# vpac_targetdb register map
Vendor: Texas Instruments
Registers are 32-bit, read-write, no defined reset value unless marked. A register's access mark holds for its fields unless they carry their own. Offsets are as the file gives them; [hi:lo] are bit positions; {n}, {i} and the like mark numbered series; 'fields as' and 'values as' point back to an identical list.

## VPAC (part 8 of 8) — Vision Pre-Processing Accelerator (VPAC)
{0xC1C+0x20*i} msram3_fw_region_{i}_end_address_h (i=0..7) — The FW Region {i} End Address High Register defines the end address bits 47 to 32 to include for the slave ksbus_msram3.slv region {i} firewall.
  [15:0] end_address_h — End address bits 47 to 32 to include in the match.
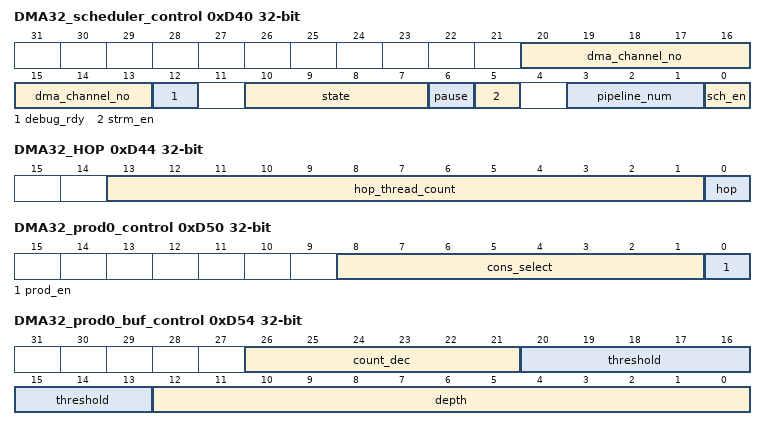
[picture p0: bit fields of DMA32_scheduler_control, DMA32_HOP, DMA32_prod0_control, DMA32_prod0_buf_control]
0xD40 DMA32_scheduler_control access per field — Scheduler Control Register
  [20:13] dma_channel_no rw — DMA channel number for thread scheduler for DMA32
  [12] debug_rdy rw — '0' -> DMA32 Scheduler resources must not be read during halted state. '1'-> DMA32 Scheduler resources are readable during halted state
  [10:7] state ro — Current state of DMA32 Scheduler
  [6] pause rw — '1' -> pause/suspend scheduler , '0' -> resume scheduler
  [5] strm_en rw — '1' -> Streaming input enable, '0' No streaming input
  [3:1] pipeline_num rw — Pipeline Number of DMA32 Scheduler
  [0] sch_en rw — scheduler enable; write '1' to enable scheduler
0xD44 DMA32_HOP — Scheduler HOP Control Register. Help in detecting eop within scheduler. Once configured, it counts task/channel starts and stops issuing further starts. Specifically useful for Head of pipe dma scheduler .
  [13:1] hop_thread_count — Number of Task count for Head of pipe
  [0] hop — '1' -> Head of Pipe producer Sch , '0' -> No hop
0xD50 DMA32_prod0_control — Controlling producer socket0 for DMA32
  [8:1] cons_select — consumer select for DMA32 prod socket 0. Used in decrementing count of producer buffer
  [0] prod_en — '1' -> Producer socket 0 enable , '0' Disable
0xD54 DMA32_prod0_buf_control — Controlling producer socket0 buffer for DMA32
  [26:21] count_dec — Count decrement value for prod count
  [20:13] threshold — Count threshold to generate pend for consumer
  [12:0] depth — Maximum number of producer buffer count
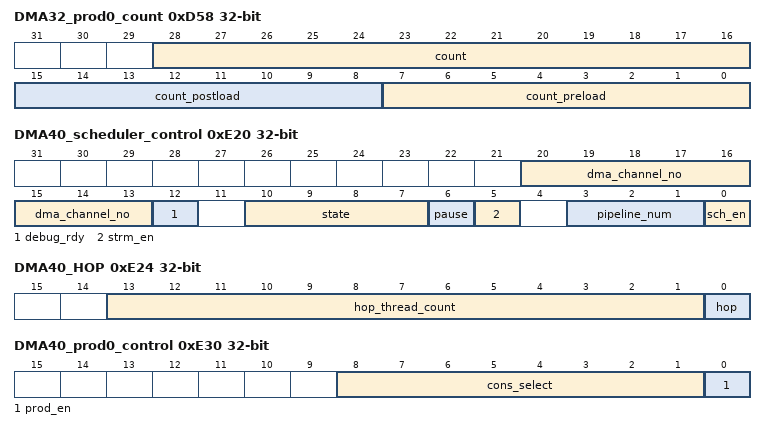
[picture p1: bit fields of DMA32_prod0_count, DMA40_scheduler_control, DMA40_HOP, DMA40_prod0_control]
0xD58 DMA32_prod0_count access per field — Defining count values for pre/post load for generating pend by DMA32 prod0
  [28:16] count ro — current count value
  [15:8] count_postload rw — count postload after producer max thread count reached
  [7:0] count_preload rw — count preload after scheduler start/init
0xE20 DMA40_scheduler_control access per field — Scheduler Control Register
  [20:13] dma_channel_no rw — DMA channel number for thread scheduler for DMA40
  [12] debug_rdy rw — '0' -> DMA40 Scheduler resources must not be read during halted state. '1'-> DMA40 Scheduler resources are readable during halted state
  [10:7] state ro — Current state of DMA40 Scheduler
  [6] pause rw — '1' -> pause/suspend scheduler , '0' -> resume scheduler
  [5] strm_en rw — '1' -> Streaming input enable, '0' No streaming input
  [3:1] pipeline_num rw — Pipeline Number of DMA40 Scheduler
  [0] sch_en rw — scheduler enable; write '1' to enable scheduler
0xE24 DMA40_HOP — Scheduler HOP Control Register. Help in detecting eop within scheduler. Once configured, it counts task/channel starts and stops issuing further starts. Specifically useful for Head of pipe dma scheduler .
  fields as DMA32_HOP
0xE30 DMA40_prod0_control — Controlling producer socket0 for DMA40
  [8:1] cons_select — consumer select for DMA40 prod socket 0. Used in decrementing count of producer buffer
  [0] prod_en — '1' -> Producer socket 0 enable , '0' Disable
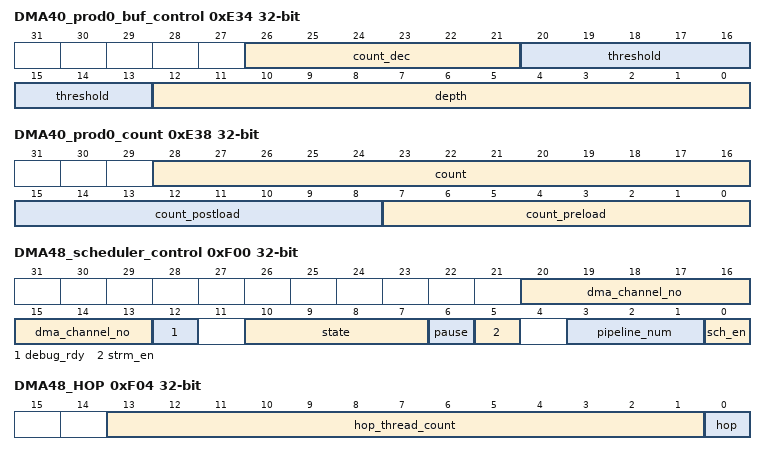
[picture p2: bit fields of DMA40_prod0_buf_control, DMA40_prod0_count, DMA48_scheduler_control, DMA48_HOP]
0xE34 DMA40_prod0_buf_control — Controlling producer socket0 buffer for DMA40
  fields as DMA32_prod0_buf_control
0xE38 DMA40_prod0_count access per field — Defining count values for pre/post load for generating pend by DMA40 prod0
  fields as DMA32_prod0_count
0xF00 DMA48_scheduler_control access per field — Scheduler Control Register
  [20:13] dma_channel_no rw — DMA channel number for thread scheduler for DMA48
  [12] debug_rdy rw — '0' -> DMA48 Scheduler resources must not be read during halted state. '1'-> DMA48 Scheduler resources are readable during halted state
  [10:7] state ro — Current state of DMA48 Scheduler
  [6] pause rw — '1' -> pause/suspend scheduler , '0' -> resume scheduler
  [5] strm_en rw — '1' -> Streaming input enable, '0' No streaming input
  [3:1] pipeline_num rw — Pipeline Number of DMA48 Scheduler
  [0] sch_en rw — scheduler enable; write '1' to enable scheduler
0xF04 DMA48_HOP — Scheduler HOP Control Register. Help in detecting eop within scheduler. Once configured, it counts task/channel starts and stops issuing further starts. Specifically useful for Head of pipe dma scheduler .
  fields as DMA32_HOP
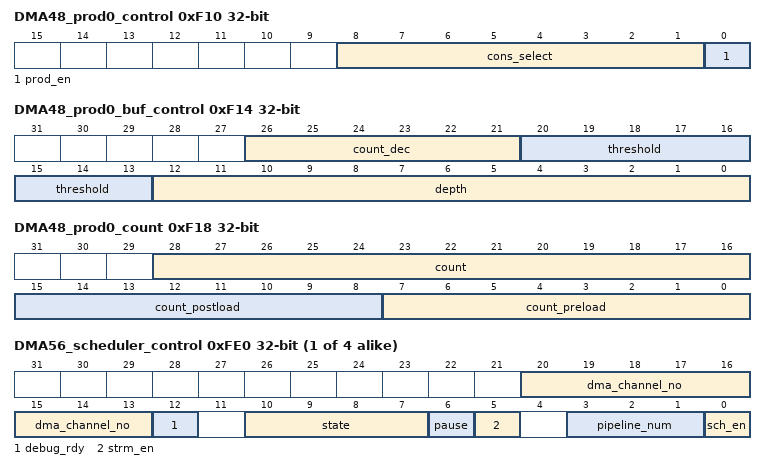
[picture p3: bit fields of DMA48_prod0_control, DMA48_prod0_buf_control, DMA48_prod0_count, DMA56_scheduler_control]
0xF10 DMA48_prod0_control — Controlling producer socket0 for DMA48
  [8:1] cons_select — consumer select for DMA48 prod socket 0. Used in decrementing count of producer buffer
  [0] prod_en — '1' -> Producer socket 0 enable , '0' Disable
0xF14 DMA48_prod0_buf_control — Controlling producer socket0 buffer for DMA48
  fields as DMA32_prod0_buf_control
0xF18 DMA48_prod0_count access per field — Defining count values for pre/post load for generating pend by DMA48 prod0
  fields as DMA32_prod0_count
{0x9C0+0x1C*i} DMA{i}_scheduler_control access per field (i=56..59) — Scheduler Control Register
  [20:13] dma_channel_no rw — DMA channel number for thread scheduler for DMA{i}
  [12] debug_rdy rw — '0' -> DMA{i} Scheduler resources must not be read during halted state. '1'-> DMA{i} Scheduler resources are readable during halted state
  [10:7] state ro — Current state of DMA{i} Scheduler
  [6] pause rw — '1' -> pause/suspend scheduler , '0' -> resume scheduler
  [5] strm_en rw — '1' -> Streaming input enable, '0' No streaming input
  [3:1] pipeline_num rw — Pipeline Number of DMA{i} Scheduler
  [0] sch_en rw — scheduler enable; write '1' to enable scheduler
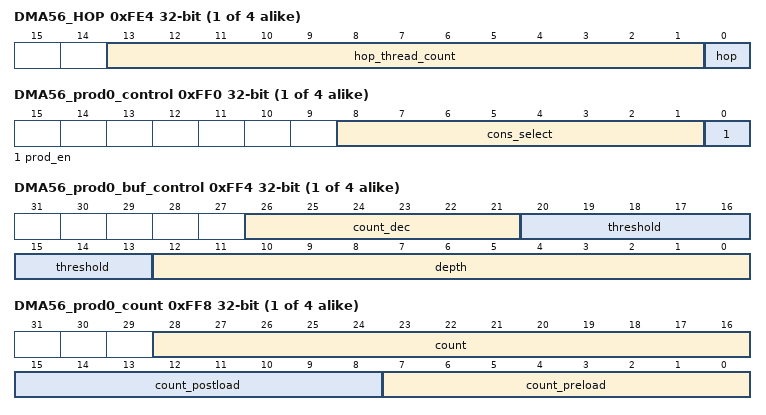
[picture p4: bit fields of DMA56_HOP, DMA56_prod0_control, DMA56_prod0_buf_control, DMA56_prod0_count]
{0x9C4+0x1C*i} DMA{i}_HOP (i=56..59) — Scheduler HOP Control Register. Help in detecting eop within scheduler. Once configured, it counts task/channel starts and stops issuing further starts. Specifically useful for Head of pipe dma scheduler .
  fields as DMA32_HOP
{0x9D0+0x1C*i} DMA{i}_prod0_control (i=56..59) — Controlling producer socket0 for DMA{i}
  [8:1] cons_select — consumer select for DMA{i} prod socket 0. Used in decrementing count of producer buffer
  [0] prod_en — '1' -> Producer socket 0 enable , '0' Disable
{0x9D4+0x1C*i} DMA{i}_prod0_buf_control (i=56..59) — Controlling producer socket0 buffer for DMA{i}
  fields as DMA32_prod0_buf_control
{0x9D8+0x1C*i} DMA{i}_prod0_count access per field (i=56..59) — Defining count values for pre/post load for generating pend by DMA{i} prod0
  fields as DMA32_prod0_count
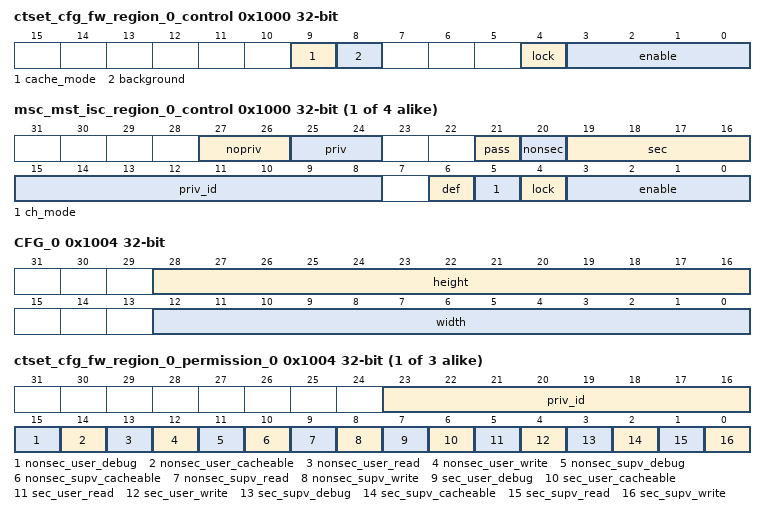
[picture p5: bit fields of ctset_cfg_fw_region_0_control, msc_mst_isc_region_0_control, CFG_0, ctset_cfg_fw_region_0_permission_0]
0x1000 ctset_cfg_fw_region_0_control — The FW Region 0 Control Register defines the control fields for the slave ctset2_wrap.cfg region 0 firewall.
  [9] cache_mode — Cache mode for region. Set to 1 to check cache permissions. Set to 0 to ignore cache permissions.
  [8] background — Background enable for region. There can be 1 backgroun region per FW and foreground regions can have overlapping addresses only with the background region.
  [4] lock — Lock region. Once set region values cannot be modified.
  [3:0] enable — Enable region. A value of 0xA enables, others disable.
{0x1000+0x20*i} msc_mst_isc_region_{i}_control access per field (i=0..3) — The ISC Region {i} Control Register defines the control fields for the master .msc_mst region {i} ISC.
  [27:26] nopriv rw — Clear output priv attribute. If each bit is set then the outgoing priv bit is cleared.
  [25:24] priv rw — Set outgoing priv attribute. If each bit is set then the outgoing priv bit is set.
  [21] pass rw — No privID replacement, pass through value.
  [20] nonsec rw — Make outgoing non-secure.
  [19:16] sec rw — Make outgoing secure. A value of 0xA enables, others disable.
  [15:8] priv_id rw
  [6] def ro — Default region indication. The default region is used when all other regions do not match.
  [5] ch_mode rw — Enable channel mode to match region to a chanid value. Otherwise use address mode to match region to an address range.
  [4] lock rw — Lock region. Once set the region values cannot be modified.
  [3:0] enable rw — Enable region. A value of 0xA enables, others disable.
0x1004 CFG_0 — The Control Register controls the input width and height of the module.
  [28:16] height — Height of the input image
  [12:0] width — Width of the input image
{0x1004+4i} ctset_cfg_fw_region_0_permission_{i} (i=0..2) — The FW Region 0 Permission {i} Register defines the permissions for the slave ctset2_wrap.cfg region 0 firewall.
  [23:16] priv_id — Allowed privid.
  [15] nonsec_user_debug — Non-secure user debug allowed.
  [14] nonsec_user_cacheable — Non-secure user cacheable allowed.
  [13] nonsec_user_read — Non-secure user read allowed.
  [12] nonsec_user_write — Non-secure user write allowed.
  [11] nonsec_supv_debug — Non-secure supervisor debug allowed.
  [10] nonsec_supv_cacheable — Non-secure supervisor cacheable allowed.
  [9] nonsec_supv_read — Non-secure supervisor read allowed.
  [8] nonsec_supv_write — Non-secure supervisor write allowed.
  [7] sec_user_debug — Secure user debug allowed.
  [6] sec_user_cacheable — Secure user cacheable allowed.
  [5] sec_user_read — Secure user read allowed.
  [4] sec_user_write — Secure user write allowed.
  [3] sec_supv_debug — Secure supervisor debug allowed.
  [2] sec_supv_cacheable — Secure supervisor cacheable allowed.
  [1] sec_supv_read — Secure supervisor read allowed.
  [0] sec_supv_write — Secure supervisor write allowed.
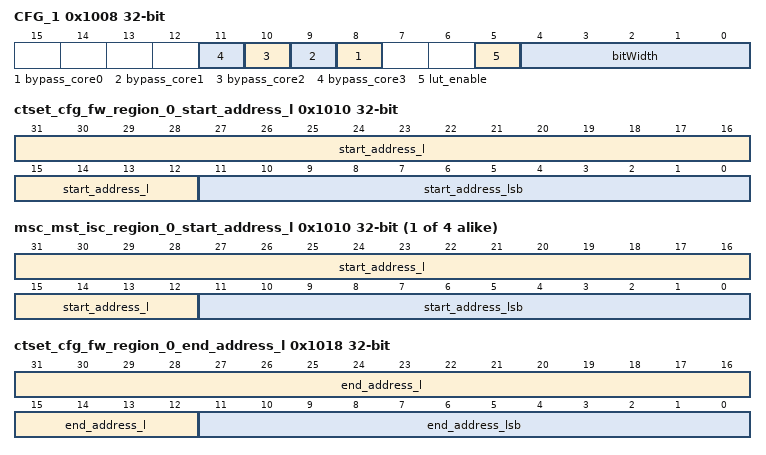
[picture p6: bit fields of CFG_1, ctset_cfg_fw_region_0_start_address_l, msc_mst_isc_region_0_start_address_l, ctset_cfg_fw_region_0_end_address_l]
0x1008 CFG_1 — The Control Register identifies the bit width of the input image
  [n+8] bypass_core{n} (n=0..3) — Setting the ~ibypass_core{n} bit will bypass filtering operation, output = input
  [5] lut_enable — 0->Use shift(bitwidth-12) ,1->Use LUT
  [4:0] bitWidth — BitWidth of the input image, values greater than 16 will be treated as 16 and values less than 12 will be treated as 12.
0x1008 LINE_SEL — Selector for which line memory is read or written
  [2:0] line_selector — Selects which line is read or written from the line memory array. The current line is updated at Start-Of-Line, so if the memory is read during a line that is being written, the data for the current_line will contain the new data for this current_line as well as old data from current_line - 5 that has not been overridden yet. If the current_line is the first few lines of a frame, the other lines will be from the end of the previous frame. '0' = current line written, '1' = current line - 1, 2 = current line - 2, 3 = current line - 3, 4 = current side band line. 5 = current side band line - 1.
0x1010 ctset_cfg_fw_region_0_start_address_l access per field — The FW Region 0 Start Address Low Register defines the start address bits 31 to 0 for the slave ctset2_wrap.cfg region 0 firewall.
  [31:12] start_address_l rw — Start address bits 31 to 12. Lowest 12 bits are forced to 0 as address must be 4KB aligned.
  [11:0] start_address_lsb ro — Start address bits 11 to 0 are forced to 0 as address must be 4KB aligned.
{0x1010+0x20*i} msc_mst_isc_region_{i}_start_address_l (i=0..3) — The ISC Region {i} Start Address Low Register defines the start address bits 31 to 0 for the master .msc_mst region {i} ISC.
  [31:12] start_address_l — Start address bits 31 to 12.
  [11:0] start_address_lsb — Start address bits 11 to 0 must be 0 as address must be 4KB aligned in address mode. Can also be channel number in channel mode.
0x1014 ctset_cfg_fw_region_0_start_address_h — The FW Region 0 Start Address High Register defines the start address bits 47 to 32 for the slave ctset2_wrap.cfg region 0 firewall.
  [15:0] start_address_h — Start address bits 47 to 32.
{0x1014+0x20*i} msc_mst_isc_region_{i}_start_address_h (i=0..3) — The ISC Region {i} Start Address High Register defines the start address bits 47 to 32 for the master .msc_mst region {i} ISC.
  [15:0] start_address_h — Start address bits 47 to 32.
0x1018 ctset_cfg_fw_region_0_end_address_l access per field — The FW Region 0 End Address Low Register defines the end address bits 31 to 0 to include for the slave ctset2_wrap.cfg region 0 firewall.
  [31:12] end_address_l rw — End address bits 31 to 12 to include in the match. Lowest 12 bits are forced to 1s as address must be 4KB aligned.
  [11:0] end_address_lsb ro — End address bits 11 to 0 are forced to 1s as address must be 4KB aligned minus 1.
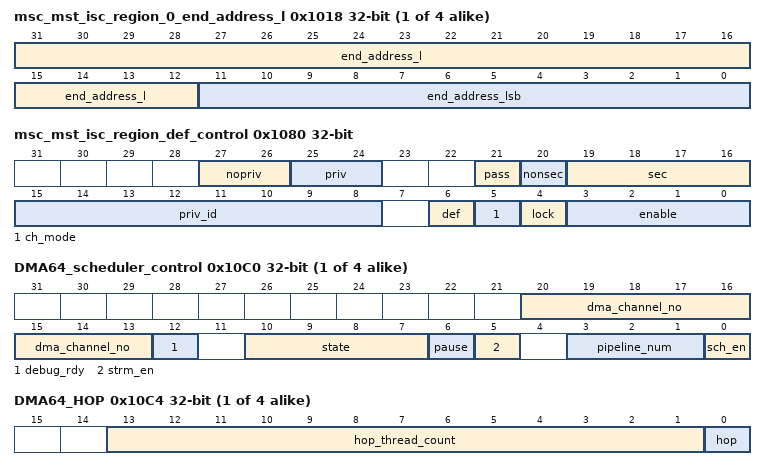
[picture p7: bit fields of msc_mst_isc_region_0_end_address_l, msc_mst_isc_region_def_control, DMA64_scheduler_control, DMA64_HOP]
{0x1018+0x20*i} msc_mst_isc_region_{i}_end_address_l access per field (i=0..3) — The ISC Region {i} End Address Low Register defines the end included address bits 31 to 0 for the master .msc_mst region {i} ISC.
  [31:12] end_address_l rw — End address bits 31 to 12 to include in the match.
  [11:0] end_address_lsb ro — End address bits 11 to 0 are forced to Fs as address must be 4KB aligned.
0x101C ctset_cfg_fw_region_0_end_address_h — The FW Region 0 End Address High Register defines the end address bits 47 to 32 to include for the slave ctset2_wrap.cfg region 0 firewall.
  fields as msram3_fw_region_0_end_address_h
{0x101C+0x20*i} msc_mst_isc_region_{i}_end_address_h (i=0..3) — The ISC Region {i} End Address High Register defines the end address bits 47 to 32 for the master .msc_mst region {i} ISC.
  [15:0] end_address_h — End address bits 47 to 32.
0x1080 msc_mst_isc_region_def_control access per field — The ISC Default Region Control Register defines the control fields for the master .msc_mst region 4 ISC.
  [27:26] nopriv rw — Clear output priv attribute. If each bit is set then the outgoing priv bit is cleared.
  [25:24] priv rw — Set outgoing priv attribute. If each bit is set then the outgoing priv bit is set.
  [21] pass rw — No privID replacement, pass through value.
  [20] nonsec rw — Make outgoing non-secure.
  [19:16] sec rw — Make outgoing secure. A value of 0xA enables, others disable.
  [15:8] priv_id rw
  [6] def ro — Default region indication. The default region is used when all other regions do not match.
  [5] ch_mode ro — Enable channel mode to match region to a chanid value. Otherwise use address mode to match region to an address range.
  [4] lock rw — Lock region. Once set, the region values cannot be modified.
  [3:0] enable ro — Enable region. A value of 0xA enables, others disable.
{0x9C0+0x1C*i} DMA{i}_scheduler_control access per field (i=64..67) — Scheduler Control Register
  fields as DMA56_scheduler_control
{0x9C4+0x1C*i} DMA{i}_HOP (i=64..67) — Scheduler HOP Control Register. Help in detecting eop within scheduler. Once configured, it counts task/channel starts and stops issuing further starts. Specifically useful for Head of pipe dma scheduler .
  fields as DMA32_HOP
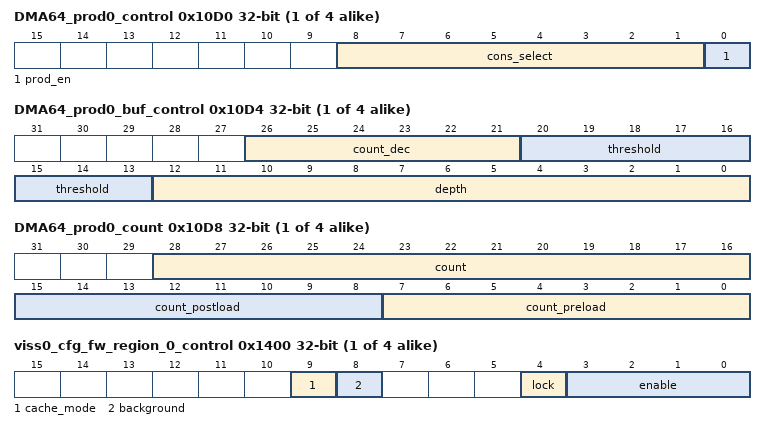
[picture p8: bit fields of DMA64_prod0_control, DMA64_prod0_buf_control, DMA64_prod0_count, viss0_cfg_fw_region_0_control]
{0x9D0+0x1C*i} DMA{i}_prod0_control (i=64..67) — Controlling producer socket0 for DMA{i}
  fields as DMA56_prod0_control
{0x9D4+0x1C*i} DMA{i}_prod0_buf_control (i=64..67) — Controlling producer socket0 buffer for DMA{i}
  fields as DMA32_prod0_buf_control
{0x9D8+0x1C*i} DMA{i}_prod0_count access per field (i=64..67) — Defining count values for pre/post load for generating pend by DMA{i} prod0
  fields as DMA32_prod0_count
{0x1400+0x20*i} viss0_cfg_fw_region_{i}_control (i=0..3) — The FW Region {i} Control Register defines the control fields for the slave ^+vpac_viss0.s_vbusp region {i} firewall.
  fields as ctset_cfg_fw_region_0_control
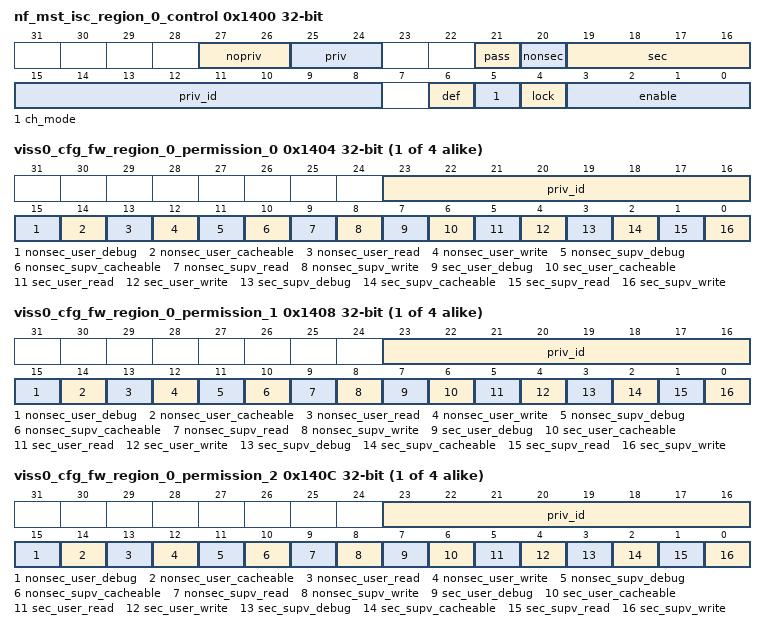
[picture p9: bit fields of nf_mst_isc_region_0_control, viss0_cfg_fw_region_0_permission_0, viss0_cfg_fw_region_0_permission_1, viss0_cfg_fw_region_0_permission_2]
0x1400 nf_mst_isc_region_0_control access per field — The ISC Region 0 Control Register defines the control fields for the master .nf_mst region 0 ISC.
  fields as msc_mst_isc_region_0_control
{0x1404+0x20*i} viss0_cfg_fw_region_{i}_permission_0 (i=0..3) — The FW Region {i} Permission 0 Register defines the permissions for the slave ^+vpac_viss0.s_vbusp region {i} firewall.
  fields as ctset_cfg_fw_region_0_permission_0
{0x1408+0x20*i} viss0_cfg_fw_region_{i}_permission_1 (i=0..3) — The FW Region {i} Permission 1 Register defines the permissions for the slave ^+vpac_viss0.s_vbusp region {i} firewall.
  fields as ctset_cfg_fw_region_0_permission_0
{0x140C+0x20*i} viss0_cfg_fw_region_{i}_permission_2 (i=0..3) — The FW Region {i} Permission 2 Register defines the permissions for the slave ^+vpac_viss0.s_vbusp region {i} firewall.
  fields as ctset_cfg_fw_region_0_permission_0
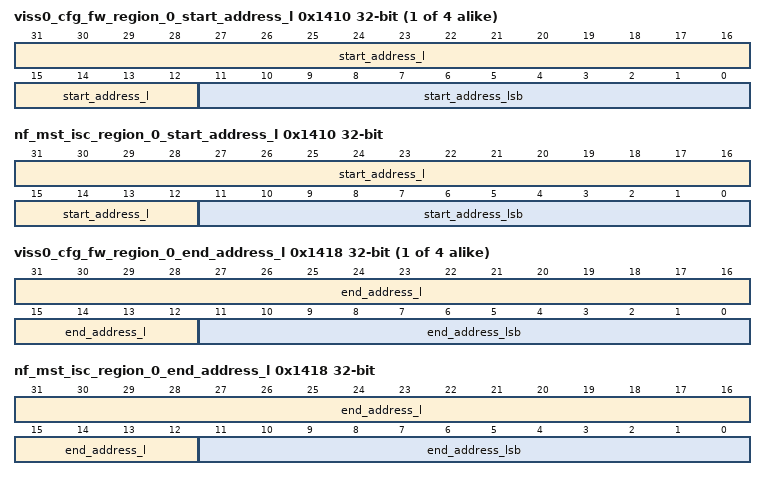
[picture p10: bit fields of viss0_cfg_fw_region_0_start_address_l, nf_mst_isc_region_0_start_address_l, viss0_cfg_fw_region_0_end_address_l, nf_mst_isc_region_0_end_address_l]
{0x1410+0x20*i} viss0_cfg_fw_region_{i}_start_address_l access per field (i=0..3) — The FW Region {i} Start Address Low Register defines the start address bits 31 to 0 for the slave ^+vpac_viss0.s_vbusp region {i} firewall.
  fields as ctset_cfg_fw_region_0_start_address_l
0x1410 nf_mst_isc_region_0_start_address_l — The ISC Region 0 Start Address Low Register defines the start address bits 31 to 0 for the master .nf_mst region 0 ISC.
  fields as msc_mst_isc_region_0_start_address_l
{0x1414+0x20*i} viss0_cfg_fw_region_{i}_start_address_h (i=0..3) — The FW Region {i} Start Address High Register defines the start address bits 47 to 32 for the slave ^+vpac_viss0.s_vbusp region {i} firewall.
  [15:0] start_address_h — Start address bits 47 to 32.
0x1414 nf_mst_isc_region_0_start_address_h — The ISC Region 0 Start Address High Register defines the start address bits 47 to 32 for the master .nf_mst region 0 ISC.
  [15:0] start_address_h — Start address bits 47 to 32.
{0x1418+0x20*i} viss0_cfg_fw_region_{i}_end_address_l access per field (i=0..3) — The FW Region {i} End Address Low Register defines the end address bits 31 to 0 to include for the slave ^+vpac_viss0.s_vbusp region {i} firewall.
  fields as ctset_cfg_fw_region_0_end_address_l
0x1418 nf_mst_isc_region_0_end_address_l access per field — The ISC Region 0 End Address Low Register defines the end included address bits 31 to 0 for the master .nf_mst region 0 ISC.
  fields as msc_mst_isc_region_0_end_address_l
{0x141C+0x20*i} viss0_cfg_fw_region_{i}_end_address_h (i=0..3) — The FW Region {i} End Address High Register defines the end address bits 47 to 32 to include for the slave ^+vpac_viss0.s_vbusp region {i} firewall.
  fields as msram3_fw_region_0_end_address_h
0x141C nf_mst_isc_region_0_end_address_h — The ISC Region 0 End Address High Register defines the end address bits 47 to 32 for the master .nf_mst region 0 ISC.
  [15:0] end_address_h — End address bits 47 to 32.
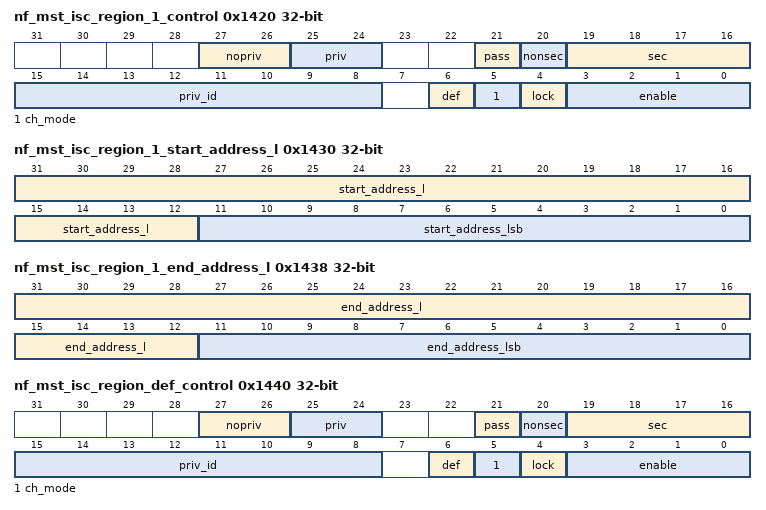
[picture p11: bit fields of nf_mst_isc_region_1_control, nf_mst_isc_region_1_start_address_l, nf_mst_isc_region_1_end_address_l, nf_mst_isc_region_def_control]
0x1420 nf_mst_isc_region_1_control access per field — The ISC Region 1 Control Register defines the control fields for the master .nf_mst region 1 ISC.
  fields as msc_mst_isc_region_0_control
0x1430 nf_mst_isc_region_1_start_address_l — The ISC Region 1 Start Address Low Register defines the start address bits 31 to 0 for the master .nf_mst region 1 ISC.
  fields as msc_mst_isc_region_0_start_address_l
0x1434 nf_mst_isc_region_1_start_address_h — The ISC Region 1 Start Address High Register defines the start address bits 47 to 32 for the master .nf_mst region 1 ISC.
  [15:0] start_address_h — Start address bits 47 to 32.
0x1438 nf_mst_isc_region_1_end_address_l access per field — The ISC Region 1 End Address Low Register defines the end included address bits 31 to 0 for the master .nf_mst region 1 ISC.
  fields as msc_mst_isc_region_0_end_address_l
0x143C nf_mst_isc_region_1_end_address_h — The ISC Region 1 End Address High Register defines the end address bits 47 to 32 for the master .nf_mst region 1 ISC.
  [15:0] end_address_h — End address bits 47 to 32.
0x1440 nf_mst_isc_region_def_control access per field — The ISC Default Region Control Register defines the control fields for the master .nf_mst region 2 ISC.
  fields as msc_mst_isc_region_def_control
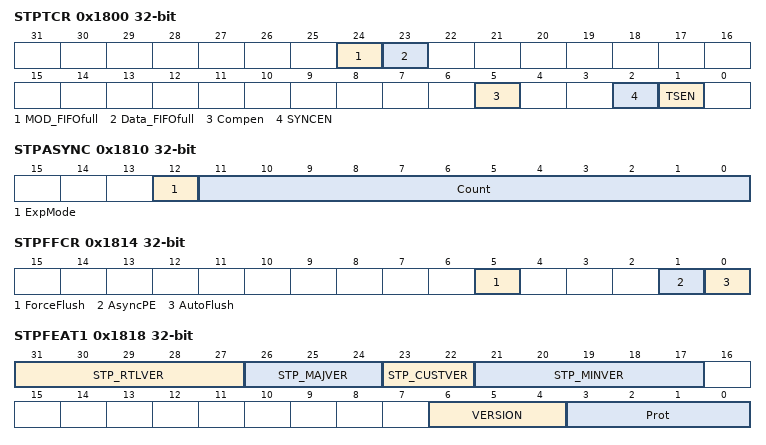
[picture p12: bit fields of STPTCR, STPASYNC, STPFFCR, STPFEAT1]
0x1800 STPTCR access per field — STP Trace Control Register
  [24] MOD_FIFOfull ro — STPMI2ATB internal MID packet fifo is full
  [23] Data_FIFOfull ro — STPMI2ATB internal Data packet fifo is full
  [5] Compen rw — Compression of Data enable
  [2] SYNCEN ro — The value 1 indicates STPASYNC is supported
  [1] TSEN rw — Timestamp Enable. This bit is static and should not be changed dynamically. This should be changed before client is enabled.
0x1804 STPTID access per field — STP Trace ID Register
  [6:0] TRACEID rw — Trace ID value. Software may overwrite the value at any time, but this is only recommended for scenarios where top-level configuration errors result in a collision between HW master IDs
0x1810 STPASYNC access per field — STP Synchronization Control Register
  [12] ExpMode rw — Exponent mode, A value of 1 sets count to 2 to the Nth, where Nth is ((bits 11 : 8)+12). A value of 0 sets Count to N (bits 11 : 0)
  [11:0] Count rw — The number of bytes between Synchronization packets
0x1814 STPFFCR access per field — STP Flush Control Register
  [5] ForceFlush rw — Write a 1 to force a flush, automatically clears after the operation is complete
  [1] AsyncPE rw — Async Priority Enable. 0 indicates ASYNC packet priority is lower than trace. 1 indicates priority escalates on second synchronization request
  [0] AutoFlush rw — Auto flush enable. When set, on every complete data (ATDATA : WIDTH) in the fifo written, data is exported out when ATREADY is asserted. This should be written before client IP enabled
0x1818 STPFEAT1 ro — STP Features 1 Register
  [31:27] STP_RTLVER — RTL Version. Reset each time major or minor version is updated
  [26:24] STP_MAJVER — Functional Major Version. This is the first version of STPMI2ATB
  [23:22] STP_CUSTVER — Custom Version (not used)
  [21:17] STP_MINVER — Functional Minor Version
  [6:4] VERSION — STP2.0 Time Stamp, Value of 011 indicates Natural binary timestamp, a value of 100 indicates gray binary timestamps
  [3:0] Prot — Protocol Revision. Value of 0001 indicates STP 2.0
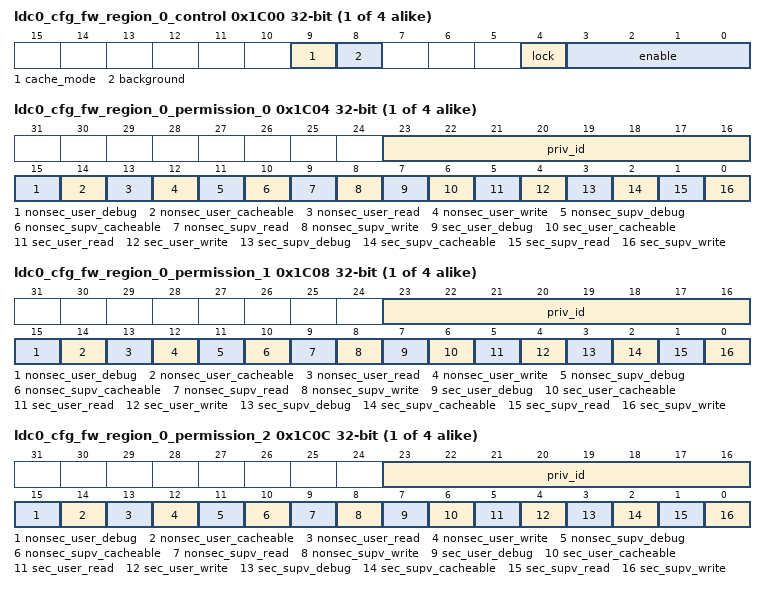
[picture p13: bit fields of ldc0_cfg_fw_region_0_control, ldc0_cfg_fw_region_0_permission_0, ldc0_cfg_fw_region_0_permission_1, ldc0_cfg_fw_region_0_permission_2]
{0x1C00+0x20*i} ldc0_cfg_fw_region_{i}_control (i=0..3) — The FW Region {i} Control Register defines the control fields for the slave ^+vpac_ldc0.s_vbusp region {i} firewall.
  fields as ctset_cfg_fw_region_0_control
{0x1C04+0x20*i} ldc0_cfg_fw_region_{i}_permission_0 (i=0..3) — The FW Region {i} Permission 0 Register defines the permissions for the slave ^+vpac_ldc0.s_vbusp region {i} firewall.
  fields as ctset_cfg_fw_region_0_permission_0
{0x1C08+0x20*i} ldc0_cfg_fw_region_{i}_permission_1 (i=0..3) — The FW Region {i} Permission 1 Register defines the permissions for the slave ^+vpac_ldc0.s_vbusp region {i} firewall.
  fields as ctset_cfg_fw_region_0_permission_0
{0x1C0C+0x20*i} ldc0_cfg_fw_region_{i}_permission_2 (i=0..3) — The FW Region {i} Permission 2 Register defines the permissions for the slave ^+vpac_ldc0.s_vbusp region {i} firewall.
  fields as ctset_cfg_fw_region_0_permission_0
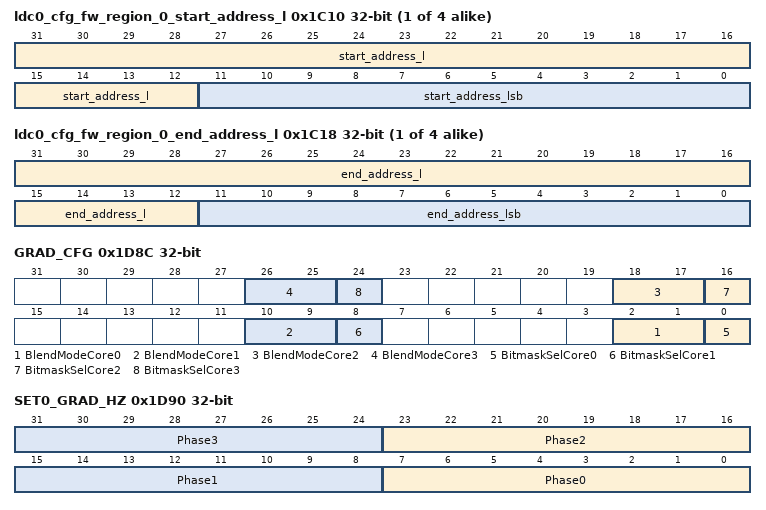
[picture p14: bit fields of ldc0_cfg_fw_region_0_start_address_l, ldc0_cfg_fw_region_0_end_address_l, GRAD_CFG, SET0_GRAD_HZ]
{0x1C10+0x20*i} ldc0_cfg_fw_region_{i}_start_address_l access per field (i=0..3) — The FW Region {i} Start Address Low Register defines the start address bits 31 to 0 for the slave ^+vpac_ldc0.s_vbusp region {i} firewall.
  fields as ctset_cfg_fw_region_0_start_address_l
{0x1C14+0x20*i} ldc0_cfg_fw_region_{i}_start_address_h (i=0..3) — The FW Region {i} Start Address High Register defines the start address bits 47 to 32 for the slave ^+vpac_ldc0.s_vbusp region {i} firewall.
  [15:0] start_address_h — Start address bits 47 to 32.
{0x1C18+0x20*i} ldc0_cfg_fw_region_{i}_end_address_l access per field (i=0..3) — The FW Region {i} End Address Low Register defines the end address bits 31 to 0 to include for the slave ^+vpac_ldc0.s_vbusp region {i} firewall.
  fields as ctset_cfg_fw_region_0_end_address_l
{0x1C1C+0x20*i} ldc0_cfg_fw_region_{i}_end_address_h (i=0..3) — The FW Region {i} End Address High Register defines the end address bits 47 to 32 to include for the slave ^+vpac_ldc0.s_vbusp region {i} firewall.
  fields as msram3_fw_region_0_end_address_h
0x1D8C GRAD_CFG — Gradient configuration for all 4 cores
  [8n+2:8n+1] BlendModeCore{n} (n=0..3) — Core-{n} Blend (0:Input-0, 1: Input0/1, 2: Input 0/1/2, 3 : Adaptive Input0/1/2 )
  [8n] BitmaskSelCore{n} (n=0..3) — Core-{n} Bitmask Select (0: Set-0 , 1: Set-1)
0x1D90 SET0_GRAD_HZ — Gradient Bitfield selector, Set-0 for Horizontal
  [8n+7:8n] Phase{n} (n=0..3) — Bitfield selector for Phase-{n}
0x1D94 SET0_GRAD_VT — Gradient Bitfield selector, Set-0 for Vertical
  [8n+7:8n] Phase{n} (n=0..3) — Bitfield selector for Phase-{n}
0x1D98 SET0_INTENSITY0 — Intensity Bitfield selector and shift for phase0/1
  [30:28] Shift_Ph1 — Intensity shift for Phase-1
  [19:16] Bitfield_Ph1 — Intensity Bitfield selector for Phase-1
  [14:12] Shift_Ph0 — Intensity shift for Phase-0
  [3:0] Bitfield_Ph0 — Intensity Bitfield selector for Phase-0
0x1D9C SET0_INTENSITY1 — Intensity Bitfield selector and shift for phase2/3
  [30:28] Shift_Ph3 — Intensity shift for Phase-3
  [19:16] Bitfield_Ph3 — Intensity Bitfield selector for Phase-3
  [14:12] Shift_Ph2 — Intensity shift for Phase-2
  [3:0] Bitfield_Ph2 — Intensity Bitfield selector for Phase-2
0x1DA0 SET1_GRAD_HZ — Gradient Bitfield selector, Set-1 for Horizontal
  [8n+7:8n] Phase{n} (n=0..3) — Bitfield selector for Phase-{n}
0x1DA4 SET1_GRAD_VT — Gradient Bitfield selector, Set-1 for Vertical
  [8n+7:8n] Phase{n} (n=0..3) — Bitfield selector for Phase-{n}
0x1DA8 SET1_INTENSITY0 — Intensity Bitfield selector and shift for phase0/1
  fields as SET0_INTENSITY0
0x1DAC SET1_INTENSITY1 — Intensity Bitfield selector and shift for phase2/3
  fields as SET0_INTENSITY1
0x1DB0 SET0_THR0_1 — Set0 Thr0_1 for H/V Grad difference
  [31:16] Thr_1 — H/V Grad diff Threshold_1
  [15:0] Thr_0 — H/V Grad diff Threshold_0
0x1DB4 SET0_THR2_3 — Set0 Thr2_3 for H/V Grad difference
  [31:16] Thr_3 — H/V Grad diff Threshold_3
  [15:0] Thr_2 — H/V Grad diff Threshold_2
0x1DB8 SET0_THR4_5 — Set0 Thr4_5 for H/V Grad difference
  [31:16] Thr_5 — H/V Grad diff Threshold_5
  [15:0] Thr_4 — H/V Grad diff Threshold_4
0x1DBC SET0_THR6 — Set0 Thr6 for H/V Grad difference
  [15:0] Thr_6 — H/V Grad diff Threshold_6
0x1DC0 SET1_THR0_1 — Set1 Thr0_1 for H/V Grad difference
  fields as SET0_THR0_1
0x1DC4 SET1_THR2_3 — Set1 Thr2_3 for H/V Grad difference
  fields as SET0_THR2_3
0x1DC8 SET1_THR4_5 — Set1 Thr4_5 for H/V Grad difference
  fields as SET0_THR4_5
0x1DCC SET1_THR6 — Set1 Thr6 for H/V Grad difference
  [15:0] Thr_6 — H/V Grad diff Threshold_6
0x1DD0 INT_STATUS — Status/clear register for flexcfa interrupts
  [2] cfa_mmr_err — status/clear for error writes to the FIR Filter MMRs during active frame causing potential frame corruption. Write 1 to clear, write 0 has no effect.
  [1] cfa_pix_err — status/clear for error on line array, set when software accesses pixel array during active frame causing potential frame corruption. Write 1 to clear, write 0 has no effect.
  [0] lut_cfg_err — status/clear for error on LUT cfg, set when software accesses LUT during active frame causing potential frame corruption. Write 1 to clear, write 0 has no effect.
0x2000 DEBUG_CTL — Enable for different debug events
  [2] sof_en — Enable for sof event
  [1] sol_en — Enable for sol event
  [0] dbg_en — Enable debug features, set to '0' to disable all debug events
0x2000 EELUT_RAM — The host will program the EE LUT RAM so that the pixels are translated from 14 bit to 12 bit using LUT entries.
  [28:16] eelut_entry_hi — The lower EE LUT entry n+1.
  [12:0] eelut_entry_lo — The lower EE LUT entry n+0.
0x2004 DEBUG_STATUS — Set/Clear for debug events
  [2] sof_event — Status/Clear for sof event, write '1' to clear
  [1] sol_event — Status/Clear for sol event, write '1' to clear
0x2008 LINE_SEL — Selector for which line memory is read or written
  [2:0] line_selector — Selects which line is read or written from the line memory array. The current line is updated at Start-Of-Line, so if the memory is read during a line that is being written, the data for the current_line will contain the new data for this current_line as well as old data from current_line - 5 that has not been overridden yet. If the current_line is the first few lines of a frame, the other lines will be from the end of the previous frame. '0' = current line written, '1' = current line - 1, 2 = current line - 2, 3 = current line - 3, 4 = current line - 4.
{0xEF4+0x14*i} DMA{i}_scheduler_control access per field (i=240..245) — Scheduler Control Register
  fields as DMA56_scheduler_control
{0xF04+0x14*i} DMA{i}_cons0_control (i=240..245) — Controlling consumer socket 0 for DMA{i}
  [9:1] prod_select — producer select for DMA{i} cons socket 0
  [0] cons_en — '1' -> Consumer socket 0 enable , '0' Disable
{0xE2C+0x14*i} DMA{i}_scheduler_control access per field (i=256..261) — Scheduler Control Register
  fields as DMA56_scheduler_control
{0xE3C+0x14*i} DMA{i}_cons0_control (i=256..261) — Controlling consumer socket 0 for DMA{i}
  fields as DMA240_cons0_control
{0xD64+0x14*i} DMA{i}_scheduler_control access per field (i=272..275) — Scheduler Control Register
  fields as DMA56_scheduler_control
{0xD74+0x14*i} DMA{i}_cons0_control (i=272..275) — Controlling consumer socket 0 for DMA{i}
  fields as DMA240_cons0_control
{0xC74+0x14*i} DMA{i}_scheduler_control access per field (i=288..291) — Scheduler Control Register
  fields as DMA56_scheduler_control
{0xC84+0x14*i} DMA{i}_cons0_control (i=288..291) — Controlling consumer socket 0 for DMA{i}
  fields as DMA240_cons0_control
{0xB84+0x14*i} DMA{i}_scheduler_control access per field (i=304..313) — Scheduler Control Register
  fields as DMA56_scheduler_control
{0xB94+0x14*i} DMA{i}_cons0_control (i=304..313) — Controlling consumer socket 0 for DMA{i}
  fields as DMA240_cons0_control
0x2400 msc_cfg_fw_region_0_control — The FW Region 0 Control Register defines the control fields for the slave ^+vpac_msc.cfg_vp region 0 firewall.
  fields as ctset_cfg_fw_region_0_control
{0x2404+4i} msc_cfg_fw_region_0_permission_{i} (i=0..2) — The FW Region 0 Permission {i} Register defines the permissions for the slave ^+vpac_msc.cfg_vp region 0 firewall.
  fields as ctset_cfg_fw_region_0_permission_0
0x240C DMA336_scheduler_control access per field — Scheduler Control Register
  [20:13] dma_channel_no rw — DMA channel number for thread scheduler for DMA336
  [12] debug_rdy rw — '0' -> DMA336 Scheduler resources must not be read during halted state. '1'-> DMA336 Scheduler resources are readable during halted state
  [10:7] state ro — Current state of DMA336 Scheduler
  [6] pause rw — '1' -> pause/suspend scheduler , '0' -> resume scheduler
  [5] strm_en rw — '1' -> Streaming input enable, '0' No streaming input
  [3:1] pipeline_num rw — Pipeline Number of DMA336 Scheduler
  [0] sch_en rw — scheduler enable; write '1' to enable scheduler
0x2410 msc_cfg_fw_region_0_start_address_l access per field — The FW Region 0 Start Address Low Register defines the start address bits 31 to 0 for the slave ^+vpac_msc.cfg_vp region 0 firewall.
  fields as ctset_cfg_fw_region_0_start_address_l
0x2414 msc_cfg_fw_region_0_start_address_h — The FW Region 0 Start Address High Register defines the start address bits 47 to 32 for the slave ^+vpac_msc.cfg_vp region 0 firewall.
  [15:0] start_address_h — Start address bits 47 to 32.
0x2418 msc_cfg_fw_region_0_end_address_l access per field — The FW Region 0 End Address Low Register defines the end address bits 31 to 0 to include for the slave ^+vpac_msc.cfg_vp region 0 firewall.
  fields as ctset_cfg_fw_region_0_end_address_l
0x241C DMA336_cons0_control — Controlling consumer socket 0 for DMA336
  [9:1] prod_select — producer select for DMA336 cons socket 0
  [0] cons_en — '1' -> Consumer socket 0 enable , '0' Disable
0x241C msc_cfg_fw_region_0_end_address_h — The FW Region 0 End Address High Register defines the end address bits 47 to 32 to include for the slave ^+vpac_msc.cfg_vp region 0 firewall.
  fields as msram3_fw_region_0_end_address_h
{0x8A0+0x14*i} DMA{i}_scheduler_control access per field (i=352..355) — Scheduler Control Register
  fields as DMA56_scheduler_control
0x2420 msc_cfg_fw_region_1_control — The FW Region 1 Control Register defines the control fields for the slave ^+vpac_msc.cfg_vp region 1 firewall.
  fields as ctset_cfg_fw_region_0_control
{0x2424+4i} msc_cfg_fw_region_1_permission_{i} (i=0..2) — The FW Region 1 Permission {i} Register defines the permissions for the slave ^+vpac_msc.cfg_vp region 1 firewall.
  fields as ctset_cfg_fw_region_0_permission_0
{0x8B0+0x14*i} DMA{i}_cons0_control (i=352..355) — Controlling consumer socket 0 for DMA{i}
  fields as DMA240_cons0_control
0x2430 msc_cfg_fw_region_1_start_address_l access per field — The FW Region 1 Start Address Low Register defines the start address bits 31 to 0 for the slave ^+vpac_msc.cfg_vp region 1 firewall.
  fields as ctset_cfg_fw_region_0_start_address_l
0x2434 msc_cfg_fw_region_1_start_address_h — The FW Region 1 Start Address High Register defines the start address bits 47 to 32 for the slave ^+vpac_msc.cfg_vp region 1 firewall.
  [15:0] start_address_h — Start address bits 47 to 32.
0x2438 msc_cfg_fw_region_1_end_address_l access per field — The FW Region 1 End Address Low Register defines the end address bits 31 to 0 to include for the slave ^+vpac_msc.cfg_vp region 1 firewall.
  fields as ctset_cfg_fw_region_0_end_address_l
0x243C msc_cfg_fw_region_1_end_address_h — The FW Region 1 End Address High Register defines the end address bits 47 to 32 to include for the slave ^+vpac_msc.cfg_vp region 1 firewall.
  fields as msram3_fw_region_0_end_address_h
{0x7B0+0x14*i} DMA{i}_scheduler_control access per field (i=368..371) — Scheduler Control Register
  fields as DMA56_scheduler_control
{0x7C0+0x14*i} DMA{i}_cons0_control (i=368..371) — Controlling consumer socket 0 for DMA{i}
  fields as DMA240_cons0_control
0x2650 pipe_dbg_cntl access per field — Pipeline Debug Control register is used by debug software to control pipeline debug behavior
  [19:17] debug_state ro — Current state of Debug activity
  [16] abort_debug wo — '1' -> Abort Debug activity on debug enabled pipelines, '0' no impact
  [6] pipe_dbg_dis_6 rw — '1' -> Pipeline6 doesn't respond to debug events, '0' Pipeline5 respond to debug events
  [n] pipe_dbg_dis_{n} rw (n=0..5) — '1' -> Pipeline{n} doesn't respond to debug events, '0' Pipeline{n} respond to debug events
0x2654 dbg_cap ro — Debug Capability register is used by debug software to determine which optional debug modules are present and how many instances of each module exist.
  [30] DBG_INT_STEP_SUP — Indicates that debug execution control can determine if single step blocks or allows interrupts. b0 No step/interrupt control b1 Step interrupt control via DBG_INT_STEP_IN
  [29] DBG_WP_DATA_SUP — Indicates if the WP resources has corresponding data qualification. b0 - Not supported. b1 - Data qualifiers are supported.
  [28] DBG_OWN_SUP — Indicates if the HWA supports an module ownership. v2.0 and above. b0 - Not Supported. b1 - Ownership supported.
  [27] DBG_INDIRECT_SUP — Indicates if the HWA supports an indirect memory access port. v2.0 and above. b0 - Not Supported. b1 - Indirect port supported.
  [26] DBG_SWBP_SUP — Whether HWA Core supports SWBP or not. b0 - Not Supported. b1 - Supported.
  [25] DBQ_RESET_SUP — Whether HWA Core reset is supported or not which does not affect debug logic. b0 - Not Supported. b1 - Supported.
  [24] SYS_EXE_REQ — Whether HWA Core Execution status and control is supported. b0 - Not Supported. b1 - Supported.
  [23] TRIG_OUTPUT — b0 - Trigger Outputs are not supported. b1 - Trigger Outputs are supported.
  [22] TRIG_INPUT — b0 - Trigger Inputs are not supported. b1 - Trigger Inputs are supported.
  [21:20] TRIG_CHNS — Number of Trigger Channels Supported. b00 ------ No channels supported. b01 ------ One channel supported. b10 ------ Two channels supported. Others ---- Reserved.
  [19:16] NUM_CNTRS — The number of counter modules that exist. The registers supporting the counter modules must be implemented consecutively in the memory map.
  [15:12] NUM_WPS — The number of watchpoint modules that exist. The registers supporting the watchpoint modules must be implemented consecutively in the memory map
  [11:8] NUM_BPS — The number of breakpoint modules that exist. The registers supporting the breakpoint modules must be implemented consecutively in the memory map.
  [7:4] REV_MAJ — Major Revision
  [3:0] REV_MIN — Minor Revision
0x2658 dbg_cntl access per field — Debug Control register is used by debug software to control all of the basic debug functions.
  [26] DBG_RESET_OCC rw — Sticky status bit to reflect reset has been generated
  [19:16] DBG_EMU0_CNTL rw — EMU0 output control. The cross trigger output control. The value in this field determines the behavior of the outputs generated on EMU0. NOTE: The effect of setting any non-zero value is ignored if the HWA Core is currently in HALTED state until the HWA core exits and re-enters HALTED state. DBG_EMUn_CNTL Output Enable Output Pulse Description 0 De-asserted 0 NA No output. Input only 1 Stopping 0 Yes Pulse on halt. If this bit is set when halted then no effect until the HWA re-enters halted state. 2 HWBP 0 Yes Pulse when any HWBP triggers 3 HWWP 0 Yes Pulse when any HWWP triggers 4 Asserted 1 No Drive pin high 5 Asserted 0 No Drive pin low 6-15 - - Reserved
  [12] DBG_HALT_EMU0 ro — Execution halted due to trigger in on EMU0 input Set to '1' when halt due to EMU0 input completes Set to '0' when execution resumes
  [11] DBG_HALT_USER ro — Execution halted due to register update of DBG_HALT Set to '1' when halt due to DBG_HALT update completes Set to '0' when execution resumes
  [10] DBG_HALT_STEP ro — Execution halted due to single step completion Set to '1' when the single step completes Set to '0' when execution resumes
  [7] DBG_EXE_STAT ro — The execution status of the module Set to '1' when halted due to debug event Set to '0' when execution resumes
  [5] DBG_EMU0_EN rw — EMU0 input trigger enable Writing '1' enables halting on the falling edge of the EMU0 input Writing '0' disables halts via EMU0 input
  [2] dbg_single_step_en rw — Single Step Execution enable. When this bit is set, the accelerator core shall be halted upon execution of a single instruction. This is after the accelerator core has left the halted state by clearing the DBG_HALT control bit. Writing '1' enables halting when the next instruction following exit from halted state is executed. Writing '0' disables halts via single step. NOTE: 1. When the accelerator core enters its natural execution state, it may or may not execute an instruction and re-enter HALTED state.
  [1] dbg_restart rw — Debug Restart Status bit.This bit is normally set when the DBG_HALT bit transitions from '1' to '0' when the natural execution state is entered.It is a sticky bit. It may also be set when a synchronous run causes the accelerator to leave halted state. Reading '1' means HWA Core exited halted state (at least temporarily). Reading '0' means HWA Core did not exit halted state. Writing '1' shall clear the bit if set. There is no restriction on when it can be cleared. Writing '0' shall have no effect.
  [0] dbg_halt rw — Global debug run control. The bit will be read as being set upon entry to HALTED state due to halted state being entered because of SWBP, HWBP, HWWP, EMU0 / 1 trigger or manual halt requested through this control. Writing '1' when read '0' shall cause a halt on the next possible halt boundary.Writing '0' when read '1' returns the system to the natural execution state.A synchronous run hardware request has the same effect.Reading '1' means that the halted state has been reached or been requested by the manual halt mechanism.Reading '0' means that the target is in its natural execution state.NOTE: 1. The natural execution state means the FSM state entered prior to last entry into Halted state. 2. This would be the last application requested FSM state unless the DBG_SYS_EXE_REQ control was used to change it.
0x2800 nf_cfg_fw_region_0_control — The FW Region 0 Control Register defines the control fields for the slave ^+vpac_nf.s_vbusp region 0 firewall.
  fields as ctset_cfg_fw_region_0_control
{0x2804+4i} nf_cfg_fw_region_0_permission_{i} (i=0..2) — The FW Region 0 Permission {i} Register defines the permissions for the slave ^+vpac_nf.s_vbusp region 0 firewall.
  fields as ctset_cfg_fw_region_0_permission_0
0x2810 nf_cfg_fw_region_0_start_address_l access per field — The FW Region 0 Start Address Low Register defines the start address bits 31 to 0 for the slave ^+vpac_nf.s_vbusp region 0 firewall.
  fields as ctset_cfg_fw_region_0_start_address_l
0x2814 nf_cfg_fw_region_0_start_address_h — The FW Region 0 Start Address High Register defines the start address bits 47 to 32 for the slave ^+vpac_nf.s_vbusp region 0 firewall.
  [15:0] start_address_h — Start address bits 47 to 32.
0x2818 nf_cfg_fw_region_0_end_address_l access per field — The FW Region 0 End Address Low Register defines the end address bits 31 to 0 to include for the slave ^+vpac_nf.s_vbusp region 0 firewall.
  fields as ctset_cfg_fw_region_0_end_address_l
0x281C nf_cfg_fw_region_0_end_address_h — The FW Region 0 End Address High Register defines the end address bits 47 to 32 to include for the slave ^+vpac_nf.s_vbusp region 0 firewall.
  fields as msram3_fw_region_0_end_address_h
{0x2C00+0x20*i} utc0_slv_cfg_fw_region_{i}_control (i=0..7) — The FW Region {i} Control Register defines the control fields for the slave dru_utc_vpac0.dru_mmr_cfg region {i} firewall.
  fields as ctset_cfg_fw_region_0_control
{0x2C04+0x20*i} utc0_slv_cfg_fw_region_{i}_permission_0 (i=0..7) — The FW Region {i} Permission 0 Register defines the permissions for the slave dru_utc_vpac0.dru_mmr_cfg region {i} firewall.
  fields as ctset_cfg_fw_region_0_permission_0
{0x2C08+0x20*i} utc0_slv_cfg_fw_region_{i}_permission_1 (i=0..7) — The FW Region {i} Permission 1 Register defines the permissions for the slave dru_utc_vpac0.dru_mmr_cfg region {i} firewall.
  fields as ctset_cfg_fw_region_0_permission_0
{0x2C0C+0x20*i} utc0_slv_cfg_fw_region_{i}_permission_2 (i=0..7) — The FW Region {i} Permission 2 Register defines the permissions for the slave dru_utc_vpac0.dru_mmr_cfg region {i} firewall.
  fields as ctset_cfg_fw_region_0_permission_0
{0x2C10+0x20*i} utc0_slv_cfg_fw_region_{i}_start_address_l access per field (i=0..7) — The FW Region {i} Start Address Low Register defines the start address bits 31 to 0 for the slave dru_utc_vpac0.dru_mmr_cfg region {i} firewall.
  fields as ctset_cfg_fw_region_0_start_address_l
{0x2C14+0x20*i} utc0_slv_cfg_fw_region_{i}_start_address_h (i=0..7) — The FW Region {i} Start Address High Register defines the start address bits 47 to 32 for the slave dru_utc_vpac0.dru_mmr_cfg region {i} firewall.
  [15:0] start_address_h — Start address bits 47 to 32.
{0x2C18+0x20*i} utc0_slv_cfg_fw_region_{i}_end_address_l access per field (i=0..7) — The FW Region {i} End Address Low Register defines the end address bits 31 to 0 to include for the slave dru_utc_vpac0.dru_mmr_cfg region {i} firewall.
  fields as ctset_cfg_fw_region_0_end_address_l
{0x2C1C+0x20*i} utc0_slv_cfg_fw_region_{i}_end_address_h (i=0..7) — The FW Region {i} End Address High Register defines the end address bits 47 to 32 to include for the slave dru_utc_vpac0.dru_mmr_cfg region {i} firewall.
  fields as msram3_fw_region_0_end_address_h
{0x3000+0x20*i} utc1_slv_cfg_fw_region_{i}_control (i=0..7) — The FW Region {i} Control Register defines the control fields for the slave dru_utc_vpac1.dru_mmr_cfg region {i} firewall.
  fields as ctset_cfg_fw_region_0_control
{0x3004+0x20*i} utc1_slv_cfg_fw_region_{i}_permission_0 (i=0..7) — The FW Region {i} Permission 0 Register defines the permissions for the slave dru_utc_vpac1.dru_mmr_cfg region {i} firewall.
  fields as ctset_cfg_fw_region_0_permission_0
{0x3008+0x20*i} utc1_slv_cfg_fw_region_{i}_permission_1 (i=0..7) — The FW Region {i} Permission 1 Register defines the permissions for the slave dru_utc_vpac1.dru_mmr_cfg region {i} firewall.
  fields as ctset_cfg_fw_region_0_permission_0
{0x300C+0x20*i} utc1_slv_cfg_fw_region_{i}_permission_2 (i=0..7) — The FW Region {i} Permission 2 Register defines the permissions for the slave dru_utc_vpac1.dru_mmr_cfg region {i} firewall.
  fields as ctset_cfg_fw_region_0_permission_0
{0x3010+0x20*i} utc1_slv_cfg_fw_region_{i}_start_address_l access per field (i=0..7) — The FW Region {i} Start Address Low Register defines the start address bits 31 to 0 for the slave dru_utc_vpac1.dru_mmr_cfg region {i} firewall.
  fields as ctset_cfg_fw_region_0_start_address_l
{0x3014+0x20*i} utc1_slv_cfg_fw_region_{i}_start_address_h (i=0..7) — The FW Region {i} Start Address High Register defines the start address bits 47 to 32 for the slave dru_utc_vpac1.dru_mmr_cfg region {i} firewall.
  [15:0] start_address_h — Start address bits 47 to 32.
{0x3018+0x20*i} utc1_slv_cfg_fw_region_{i}_end_address_l access per field (i=0..7) — The FW Region {i} End Address Low Register defines the end address bits 31 to 0 to include for the slave dru_utc_vpac1.dru_mmr_cfg region {i} firewall.
  fields as ctset_cfg_fw_region_0_end_address_l
{0x301C+0x20*i} utc1_slv_cfg_fw_region_{i}_end_address_h (i=0..7) — The FW Region {i} End Address High Register defines the end address bits 47 to 32 to include for the slave dru_utc_vpac1.dru_mmr_cfg region {i} firewall.
  fields as msram3_fw_region_0_end_address_h
0x4000 PIXEL_RAM — The pixel RAM contains the array of 12 bit pixels stored and used by the CFA logic. Pixels are 16 bit aligned. Pixels can only be written two at a time.
  [27:16] PIXEL_HI — The 12 bit pixel data for the selected line upper pixel 'n+1'
  [11:0] PIXEL_LO — The 12 bit pixel data for the selected line lower pixel 'n'
0x4000 PIXEL_RAM — The pixel RAM contains the array of 12 bit pixels stored and used by the CFA logic. Pixels are 16 bit aligned. Pixels can only be written two at a time.
  fields as PIXEL_RAM
